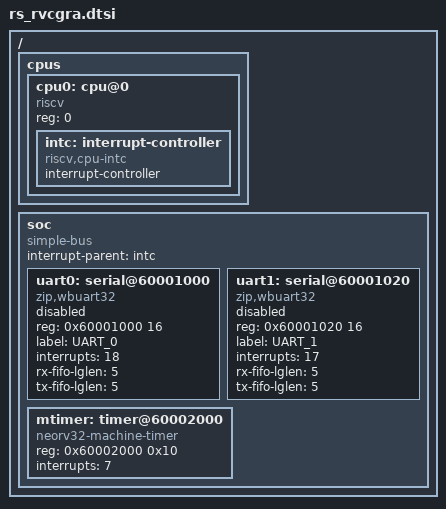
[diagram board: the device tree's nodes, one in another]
/*
 * Copyright (c) 2021 Henrik Brix Andersen <henrik@brixandersen.dk>
 *
 * SPDX-License-Identifier: Apache-2.0
 */

/dts-v1/;

#include <skeleton.dtsi>
#include <zephyr/dt-bindings/gpio/gpio.h>

/ {

	cpus {
		#address-cells = <1>;
		#size-cells = <0>;

		cpu0: cpu@0 {
			compatible = "riscv";
			reg = <0>;
			device_type = "cpu";

			intc: interrupt-controller {
				compatible = "riscv,cpu-intc";
				interrupt-controller;
				#address-cells = <1>;
				#interrupt-cells = <1>;
			};
		};
	};

	soc {
		compatible = "simple-bus";
		interrupt-parent = <&intc>;
		#address-cells = <1>;
		#size-cells = <1>;
		ranges;

		uart0: serial@60001000 {
			compatible = "zip,wbuart32";
			status = "disabled";
			reg = <0x60001000 16>;
			label = "UART_0";
			interrupts = <18>;
			interrupt-names = "shared";
			rx-fifo-lglen = <5>;
			tx-fifo-lglen = <5>;
		};
		uart1: serial@60001020 {
			compatible = "zip,wbuart32";
			status = "disabled";
			reg = <0x60001020 16>;
			label = "UART_1";
			interrupts = <17>;
			interrupt-names = "shared";
			rx-fifo-lglen = <5>;
			tx-fifo-lglen = <5>;
		};

		mtimer: timer@60002000 {
			compatible = "neorv32-machine-timer";
			reg = <0x60002000 0x10>;
			interrupts = <7>;
		};
	};
};
